VERSION ""

NS_ :

	SIG_VALTYPE_z
	SIGTYPE_VALTYPE_
	BO_TX_BU_
	BA_DEF_REL_
	BA_REL_
	BA_DEF_DEF_REL_
	BU_SG_REL_
	BU_EV_REL_
	BU_BO_REL_
	SG_MUL_VAL_

BS_:

BU_:

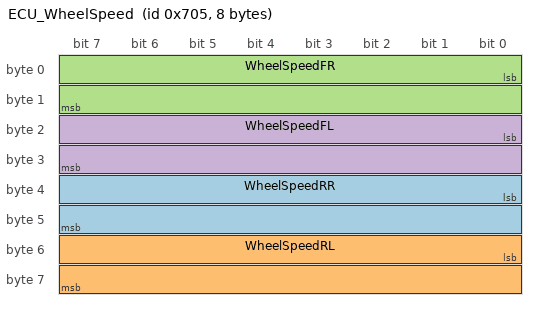
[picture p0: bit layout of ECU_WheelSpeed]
BO_ 1797 ECU_WheelSpeed: 8 Vector__XXX
 SG_ WheelSpeedRR : 32|16@1+ (0.1,0) [0|0] "km/h" Vector__XXX
 SG_ WheelSpeedRL : 48|16@1+ (0.1,0) [0|0] "km/h" Vector__XXX
 SG_ WheelSpeedFR : 0|16@1+ (0.1,0) [0|0] "km/h" Vector__XXX
 SG_ WheelSpeedFL : 16|16@1+ (0.1,0) [0|0] "km/h" Vector__XXX

BA_DEF_  "BusType" STRING ;
BA_DEF_DEF_  "BusType" "CAN";
